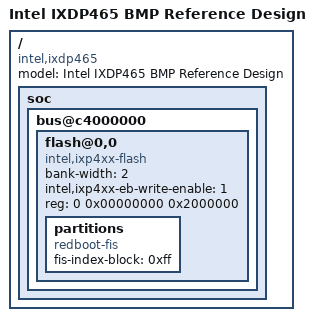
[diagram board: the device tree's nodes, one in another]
// SPDX-License-Identifier: ISC
/*
 * Device Tree file for the Intel IXDP465 Control Plane processor reference
 * design, codename "BMP".
 */

/dts-v1/;

#include "intel-ixp45x-ixp46x.dtsi"
#include "intel-ixp4xx-reference-design.dtsi"
#include <dt-bindings/input/input.h>

/ {
	model = "Intel IXDP465 BMP Reference Design";
	compatible = "intel,ixdp465", "intel,ixp46x";
	#address-cells = <1>;
	#size-cells = <1>;

	soc {
		bus@c4000000 {
			flash@0,0 {
				compatible = "intel,ixp4xx-flash", "cfi-flash";
				bank-width = <2>;
				/* Enable writes on the expansion bus */
				intel,ixp4xx-eb-write-enable = <1>;
				/* 32 MB of Flash mapped in at CS0 and CS1 */
				reg = <0 0x00000000 0x2000000>;

				partitions {
					compatible = "redboot-fis";
					/* Eraseblock at 0x1fe0000 */
					fis-index-block = <0xff>;
				};
			};
		};
		/* TODO: configure ethernet etc */
	};
};
